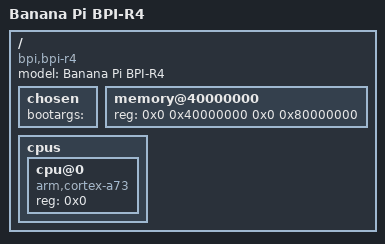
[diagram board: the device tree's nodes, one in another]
/dts-v1/;

/ {
    compatible = "bpi,bpi-r4", "mediatek,mt7988a";
    model = "Banana Pi BPI-R4";
    #address-cells = <2>;
    #size-cells = <2>;

    chosen {
        bootargs = "";
    };

    memory@40000000 {
        device_type = "memory";
        reg = <0x0 0x40000000 0x0 0x80000000>; /* 2GB */
    };

    cpus {
        #address-cells = <1>;
        #size-cells = <0>;

        cpu@0 {
            device_type = "cpu";
            compatible = "arm,cortex-a73";
            reg = <0x0>;
        };
    };
};
